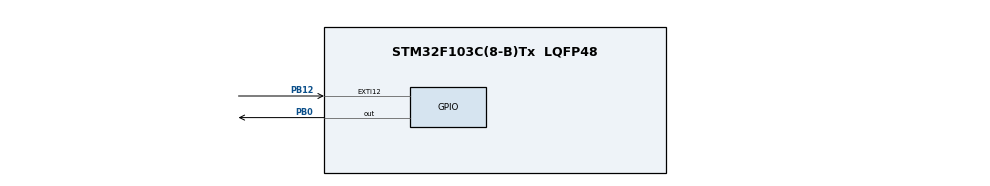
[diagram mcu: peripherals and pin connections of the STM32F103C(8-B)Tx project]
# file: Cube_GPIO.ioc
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Mcu.Family=STM32F1
Mcu.Name=STM32F103C(8-B)Tx
Mcu.Package=LQFP48
NVIC.EXTI15_10_IRQn=true\:12\:0\:true\:false\:true\:true\:true\:true
NVIC.PriorityGroup=NVIC_PRIORITYGROUP_4
PA13.Mode=Serial_Wire
PA13.Signal=SYS_JTMS-SWDIO
PA14.Mode=Serial_Wire
PA14.Signal=SYS_JTCK-SWCLK
PB0.PinState=GPIO_PIN_SET
PB0.Signal=GPIO_Output
PB12.GPIO_ModeDefaultEXTI=GPIO_MODE_IT_FALLING
PB12.GPIO_PuPd=GPIO_PULLUP
PB12.Signal=GPXTI12
PD0-OSC_IN.Mode=HSE-External-Oscillator
PD0-OSC_IN.Signal=RCC_OSC_IN
PD1-OSC_OUT.Mode=HSE-External-Oscillator
PD1-OSC_OUT.Signal=RCC_OSC_OUT
ProjectManager.HeapSize=0x200
ProjectManager.StackSize=0x400
ProjectManager.TargetToolchain=MDK-ARM V5.32
RCC.APB1Freq_Value=8000000
RCC.APB2Freq_Value=8000000
board=custom

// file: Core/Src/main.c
/* USER CODE BEGIN Header */
/**
  ******************************************************************************
  * @file           : main.c
  * @brief          : Main program body
  ******************************************************************************
  * @attention
  *
  * Copyright (c) 2023 STMicroelectronics.
  * All rights reserved.
  *
  * This software is licensed under terms that can be found in the LICENSE file
  * in the root directory of this software component.
  * If no LICENSE file comes with this software, it is provided AS-IS.
  *
  ******************************************************************************
  */
/* USER CODE END Header */
#include "main.h"
#include "gpio.h"

/* USER CODE BEGIN Includes */
#include "bsp_led.h"
#include "bsp_key.h"
/* USER CODE END Includes */

/* USER CODE BEGIN PD */
uint8_t state;
void EXTI15_10_IRQHandler(void)
{
    /* USER CODE BEGIN EXTI15_10_IRQn 0 */
    state=~state;
    LED_PB0_OFF;
    LED_PB1_OFF;
    LED_PB10_OFF;
    /* USER CODE END EXTI15_10_IRQn 0 */
    HAL_GPIO_EXTI_IRQHandler(GPIO_PIN_12);
    /* USER CODE BEGIN EXTI15_10_IRQn 1 */

    /* USER CODE END EXTI15_10_IRQn 1 */
}
/* USER CODE END PD */

void SystemClock_Config(void);

int main(void)
{

    /* MCU Configuration--------------------------------------------------------*/

    /* Reset of all peripherals, Initializes the Flash interface and the Systick. */
    HAL_Init();

    /* Configure the system clock */
    SystemClock_Config();

    /* Initialize all configured peripherals */
    MX_GPIO_Init();
    /* USER CODE BEGIN 2 */
    LED_GPIO_Init();
    KEY_GPIO_Init();
    /* USER CODE END 2 */

    /* Infinite loop */
    while (1)
    {
        while(state)
        {
            LED_PB0_ON;
            HAL_Delay(500);
            LED_PB0_OFF;
            if(!state)
                break;
            LED_PB1_ON;
            HAL_Delay(500);
            LED_PB1_OFF;
            if(!state)
                break;
            LED_PB10_ON;
            HAL_Delay(500);
            LED_PB10_OFF;
            if(!state)
                break;
            HAL_Delay(500);
        }
    }
}

void SystemClock_Config(void)
{
    RCC_OscInitTypeDef RCC_OscInitStruct = {0};
    RCC_ClkInitTypeDef RCC_ClkInitStruct = {0};

    /** Initializes the RCC Oscillators according to the specified parameters
    * in the RCC_OscInitTypeDef structure.
    */
    RCC_OscInitStruct.OscillatorType = RCC_OSCILLATORTYPE_HSI;
    RCC_OscInitStruct.HSIState = RCC_HSI_ON;
    RCC_OscInitStruct.HSICalibrationValue = RCC_HSICALIBRATION_DEFAULT;
    RCC_OscInitStruct.PLL.PLLState = RCC_PLL_NONE;
    if (HAL_RCC_OscConfig(&RCC_OscInitStruct) != HAL_OK)
    {
        Error_Handler();
    }

    /** Initializes the CPU, AHB and APB buses clocks
    */
    RCC_ClkInitStruct.ClockType = RCC_CLOCKTYPE_HCLK|RCC_CLOCKTYPE_SYSCLK
                                  |RCC_CLOCKTYPE_PCLK1|RCC_CLOCKTYPE_PCLK2;
    RCC_ClkInitStruct.SYSCLKSource = RCC_SYSCLKSOURCE_HSI;
    RCC_ClkInitStruct.AHBCLKDivider = RCC_SYSCLK_DIV1;
    RCC_ClkInitStruct.APB1CLKDivider = RCC_HCLK_DIV1;
    RCC_ClkInitStruct.APB2CLKDivider = RCC_HCLK_DIV1;

    if (HAL_RCC_ClockConfig(&RCC_ClkInitStruct, FLASH_LATENCY_0) != HAL_OK)
    {
        Error_Handler();
    }
}

void Error_Handler(void)
{
    __disable_irq();
    while (1)
    {
    }
}
